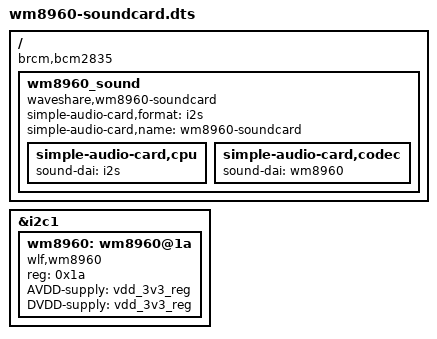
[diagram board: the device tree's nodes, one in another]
/dts-v1/;
/plugin/;

/ {
    compatible = "brcm,bcm2835";

    fragment@0 {
        target = <&i2c1>;
        __overlay__ {
            #address-cells = <1>;
            #size-cells = <0>;
            status = "okay";

            wm8960: wm8960@1a {
                compatible = "wlf,wm8960";
                reg = <0x1a>;
                #sound-dai-cells = <0>;
                AVDD-supply = <&vdd_3v3_reg>;
                DVDD-supply = <&vdd_3v3_reg>;
                status = "okay";
            };
        };
    };

    fragment@1 {
        target-path = "/";
        __overlay__ {
            wm8960_sound {
                compatible = "waveshare,wm8960-soundcard";
                simple-audio-card,format = "i2s";
                simple-audio-card,name = "wm8960-soundcard";
                status = "okay";

                simple-audio-card,cpu {
                    sound-dai = <&i2s>;
                };
                simple-audio-card,codec {
                    sound-dai = <&wm8960>;
                };
            };
        };
    };
};

